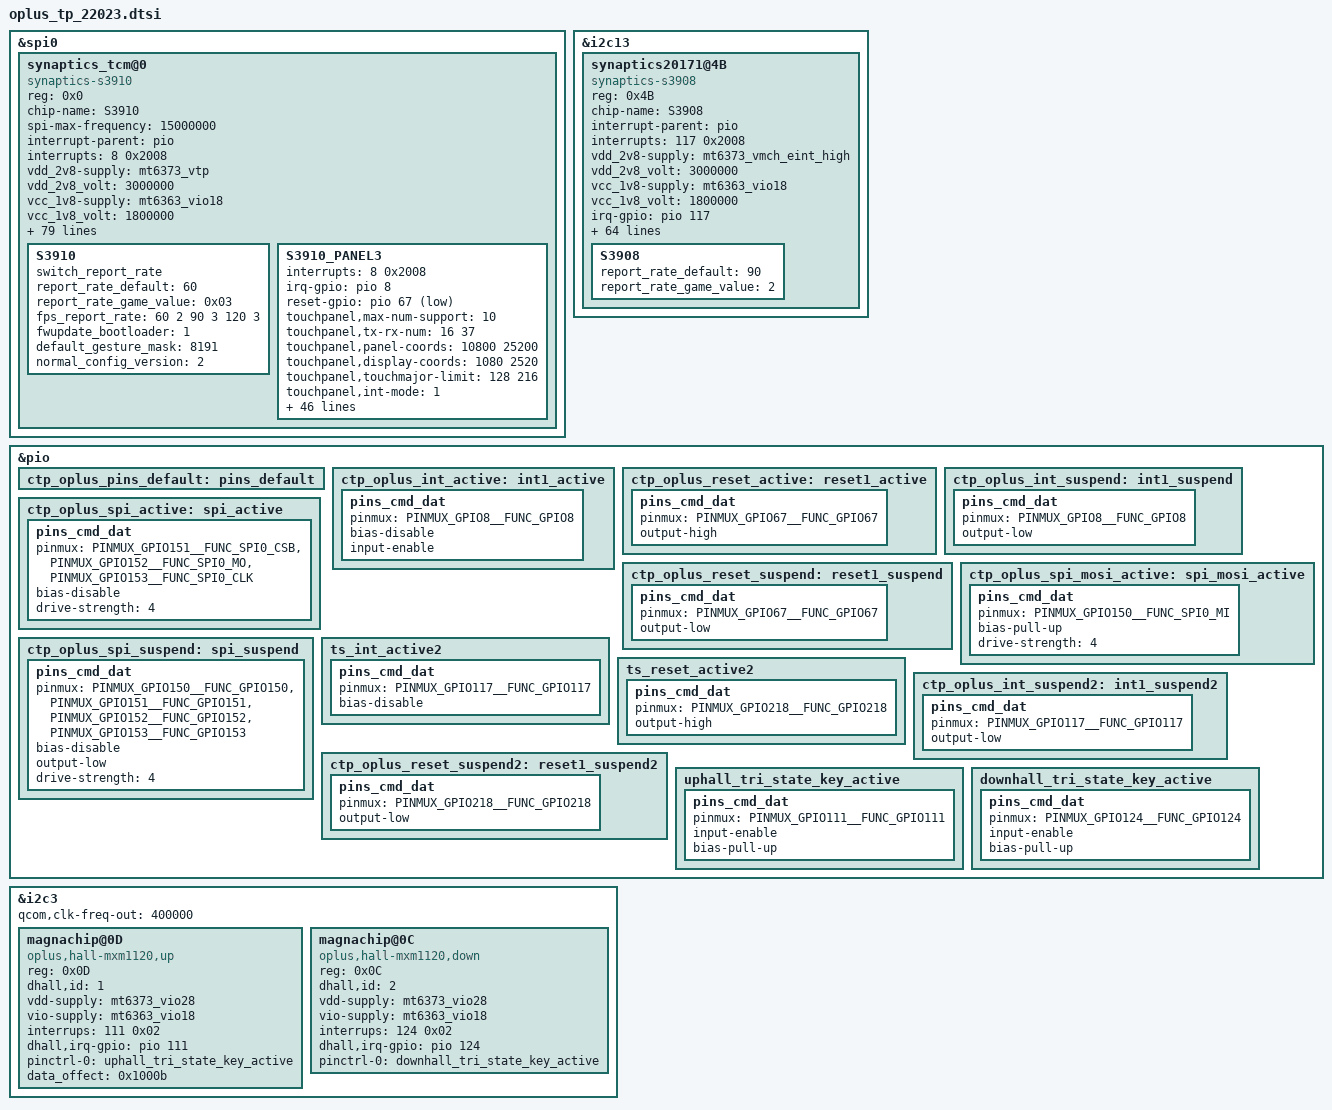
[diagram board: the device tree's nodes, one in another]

&spi0{
	status = "okay";
	#address-cells = <1>;
	#size-cells = <0>;

	synaptics_tcm@0{
		compatible = "synaptics-s3910";
		reg = <0x0>;
		chip-name = "S3910";
		status = "okay";
		spi-max-frequency = <15000000>;
		/* Interrupt && Irq-gpio */
		interrupt-parent = <&pio>;
		interrupts = <8 0x2008>;

		/* Power Config */
		//enable2v8_gpio  = <&pio 164 0x1>;
		vdd_2v8-supply  = <&mt6373_vtp>;
		vdd_2v8_volt = <3000000>;
		vcc_1v8-supply  = <&mt6363_vio18>;
		vcc_1v8_volt = <1800000>;

		/* Other HW Resource */
		irq-gpio = <&pio 8 0x2008>;
		reset-gpio = <&pio 67 0x1>;

		pinctrl-names = "default",  "oplus_int_active",
		"oplus_reset_active", "oplus_int_suspend",
		"oplus_reset_suspend", "oplus_spi_active",
		"oplus_spi_suspend";
		pinctrl-0 = <&ctp_oplus_pins_default>;
		pinctrl-1 = <&ctp_oplus_int_active>;
		pinctrl-2 = <&ctp_oplus_reset_active>;
		pinctrl-3 = <&ctp_oplus_int_suspend>;
		pinctrl-4 = <&ctp_oplus_reset_suspend>;
		pinctrl-5 = <&ctp_oplus_spi_active>, <&ctp_oplus_spi_mosi_active>;
		pinctrl-6 = <&ctp_oplus_spi_suspend>;

		touchpanel,max-num-support = <10>;
		touchpanel,tx-rx-num = <17 40>;
		earsense,tx-rx-num = <17 18>;
		touchpanel,panel-coords = <10800 25200>;
		touchpanel,display-coords = <1080 2520>;
		touchpanel,touchmajor-limit = <128 216>;
		touchpanel,elimination-range = <20 200 200>;
		touchpanel,int-mode = <1>; /*0: interrupt and disable, 1:interrupt and not disable*/
		touchpanel,smooth-level = <0 1 2 5 8 9>;
		touchpanel,smooth-level-charging = <0 2 4 8 9 10>;
		touchpanel,sensitive-level = <0 70 55 40 25 10>;
		touchpanel,single-optimized-time = <8>;
		touchpanel,high-frame-rate-time = <60>;

		touchpanel,tp-index = <0>;
		vid_len = <2>;
		panel_type = <3 8>; /*type:3 BOE  type:8 SAMSUNG*/
		platform_support_project = <22023 22223>;
		platform_support_project_dir = <22023 22023>;
		platform_support_project_commandline = "AC068_P_3_A0001_fhd_cmd","oplus22023_samsung_amf680cm01_fhd_dsi_cmd";

		prevention,curved_screen_V2;
		prevention,grip_disable_level = <6>;
		prevention,updelay_time_ms = <30>;
		prevention,makeup_cnt_weight = <5 1 2 2 2>;
		prevention,large_corner_range = <960 2400>;
		prevention,large_corner_judge_condition = <850 100 800 7 7>;
		prevention,trx_reject_condition = <8 7 7>;
		prevention,trx_strict_reject_condition = <8 6 6>;
		prevention,large_judge_time_ms = <500 50 30>;
		prevention,large_exit_condition = <8 8 2>;
		prevention,single_channel_width = <160 160>;
		prevention,normal_tap_condition = <5 350>;
		prevention,long_edge_condition = <310 220 200 60>;
		prevention,long_strict_edge_condition = <120 60>;
		prevention,long_fingerhold_condition = <70 6 4 4>;
		prevention,short_edge_condition = <280 180 180 80>;
		prevention,short_strict_edge_condition = <160 60>;
		prevention,large_strict_exit_condition = <6 6>;
		prevention,top_corner_config = <250 750 100>;
		prevention,edge_swipe_config = <150 700>;

		/* SW Support Feature Control */
		regulator_count_not_support;
		black_gesture_support;
		sportify_aod_gesture_support;
		pressure_report_support;
		charger_pump_support;
		game_switch_support;
		smart_gesture_support;
		spi_port_support;
		fw_update_app_support;
		fingerprint_underscreen_support;
		exception_upload_support;
		freq_hop_simulate_support;
		report_flow_unlock_support;
		screenoff_fingerprint_info_support;
		irq_need_dev_resume_ok;
		enable_point_auto_change;
		report_rate_white_list_support;
		kernel_grip_support;
		//grip_no_driver_support;
		health_monitor_support;
		black_gesture_indep_support;
		algorithm_support;
		snr_read_support;
		palm_to_sleep_support;
		tp_data_record_support;
		/*
		 *Virtual Key Config:
		 *1:touchpanel,button-type: <virtualkey_type  supportted_button-map>
		 *virtualkey_type:
		 *Type 1: using board_properties
		 *Type 2: using same IC (button zone&& touch zone are seprate)
		 *Type 3: using diffrent IC (button zone&& touch zone are seprate)
		 *Type 4: No need of virtual key process
		 *supportted_button-map:select|menu|home|back
		 *
		 *2:touchpanel,button-map
		 *type (X1,Y1)(X2,Y2)(X3,Y3)(Width_X,Hight_Y)--Only when button-type is 0
		 */
		touchpanel,button-type = <4>;
		touchpanel.button-TRx = <0 0>;

		S3910 {
			switch_report_rate;
			report_rate_default = <60>;
			report_rate_game_value = <0x03>;
			fps_report_rate = <60 2 90 3 120 3>;//1:360Hz 2:125Hz 3:240Hz
			fwupdate_bootloader = <1>;
			default_gesture_mask = <8191>;
			normal_config_version = <2>;
		};

		S3910_PANEL3 {
			interrupts = <8 0x2008>;
			irq-gpio = <&pio 8 0x2008>;
			reset-gpio = <&pio 67 0x1>;

			touchpanel,max-num-support = <10>;
			touchpanel,tx-rx-num = <16 37>;
			touchpanel,panel-coords = <10800 25200>;
			touchpanel,display-coords = <1080 2520>;
			touchpanel,touchmajor-limit = <128 216>;
			touchpanel,int-mode = <1>; /*0: interrupt and disable, 1:interrupt and not disable*/
			touchpanel,smooth-level = <0 1 2 5 8 9>;
			touchpanel,smooth-level-charging = <0 2 4 8 9 10>;
			touchpanel,sensitive-level = <0 140 110 80 50 20>;
			touchpanel,single-optimized-time = <8>;
			touchpanel,high-frame-rate-time = <60>;

			prevention,curved_screen_V2;
			prevention,grip_disable_level = <6>;
			prevention,updelay_time_ms = <30>;
			prevention,makeup_cnt_weight = <5 1 2 2 2>;
			prevention,large_corner_range = <960 2400>;
			prevention,large_corner_judge_condition = <850 100 800 7 7>;
			prevention,trx_reject_condition = <8 7 7>;
			prevention,trx_strict_reject_condition = <8 6 6>;
			prevention,large_judge_time_ms = <500 50 30>;
			prevention,large_exit_condition = <8 8 2>;
			prevention,single_channel_width = <160 160>;
			prevention,normal_tap_condition = <5 350>;
			prevention,long_edge_condition = <310 220 200 60>;
			prevention,long_strict_edge_condition = <120 60>;
			prevention,long_fingerhold_condition = <70 6 4 4>;
			prevention,short_edge_condition = <280 180 180 80>;
			prevention,short_strict_edge_condition = <160 60>;
			prevention,large_strict_exit_condition = <6 6>;
			prevention,top_corner_config = <250 750 100>;
			prevention,edge_swipe_config = <150 700>;

			prevention,curved_screen_V4;
			prevention,long_eliminate_point_type = <2 14400 10560 270 27720 300 1>;
			prevention,long_fingerhold_condition2 = <650 2000 0 0>;
			prevention,top_corner_config2 = <3 80 600 1500 0>;
			prevention,hor_long_top_corner_config = <350 2270 0 0>;
			prevention,top_middle_config = <14400 1000 1000 0>;
			prevention,corner_eliminate_point_type = <0 1380 2280 1>;
			prevention,finger_hold_max_rx_exit_distance = <5 350 2300>;
			prevention,max_rx_exit_distance = <1 5 150 350 2000>;
			prevention,dynamic_finger_hold_exit_distance = <1 350 2300 450>;
                        tp_data_record_support;
		};
	};

};

&i2c13 {
	status = "okay";
	synaptics20171@4B {
        status = "okay";
		compatible = "synaptics-s3908";
		reg = <0x4B>;
		chip-name = "S3908";

		/* Interrupt && Irq-gpio */
		interrupt-parent = <&pio>;
		interrupts = <117 0x2008>;

		/* Power Config */
		vdd_2v8-supply  = <&mt6373_vmch_eint_high>;
		vdd_2v8_volt = <3000000>;
		vcc_1v8-supply  = <&mt6363_vio18>;
		vcc_1v8_volt = <1800000>;
		/* Other HW Resource */

		irq-gpio = <&pio 117 0x2008>;
		reset-gpio = <&pio 218 0x1>;
		pinctrl-names = "default";
		pinctrl-0 = <&ts_int_active2 &ts_reset_active2>;

		touchpanel,max-num-support = <10>;
		touchpanel,tx-rx-num = <9 17>;
		touchpanel,panel-coords = <382 720>;
		touchpanel,display-coords = <382 720>;
		touchpanel,touchmajor-limit = <0 0>;
		touchpanel,elimination-range = <20 200 200>;
		touchpanel,int-mode = <1>; /*0: interrupt and disable, 1:interrupt and not disable*/
		touchpanel,smooth-level = <0 1 2 3 8 10>;
		touchpanel,sensitive-level = <0 88 70 64 45 10>;

		touchpanel,tp-index = <1>;
		vid_len = <2>;
		panel_type = <3>; /*type:3 BOE*/

		platform_support_project = <22023 22223>;
		platform_support_project_dir = <22023 22023>;
		platform_support_project_commandline = "default_commandline","default_commandline";

		prevention,curved_screen_V2;
		prevention,grip_disable_level = <6>;
		prevention,updelay_time_ms = <30>;
		prevention,makeup_cnt_weight = <4 1 2 2 2>;
		prevention,large_corner_range = <80 90>;
		prevention,large_corner_judge_condition = <500 100 100 6 6>;
		prevention,trx_reject_condition = <9 7 7>;
		prevention,trx_strict_reject_condition = <8 5 5>;
		prevention,large_judge_time_ms = <500 50 30>;
		prevention,large_exit_condition = <8 8 2>;
		prevention,single_channel_width = <32 32>;
		prevention,normal_tap_condition = <10 300>;
		prevention,long_edge_condition = <350 130 180 100>;
		prevention,long_strict_edge_condition = <160 60>;
		prevention,long_fingerhold_condition = <100 6 4 4>;
		prevention,short_edge_condition = <180 130 180 220>;
		prevention,short_strict_edge_condition = <160 60>;
		prevention,large_strict_exit_condition = <4 4>;
		prevention,top_corner_config = <0 0 0>;
		prevention,edge_swipe_config = <30 100>;

		/* SW Support Feature Control */
		health_monitor_support;
		black_gesture_support;
		black_gesture_indep_support;
		sportify_aod_gesture_support;
		charger_pump_support;
		lcd_tp_refresh_support;
		enable_point_auto_change;
		fw_update_app_support;
		smart_gesture_support;
		game_switch_support;
		report_flow_unlock_support;
		kernel_grip_support;
		freq_hop_simulate_support;
 		pressure_report_support;
		exception_upload_support;
		touchpanel,single-optimized-time = <8>;
 		touchpanel,high-frame-rate-time = <60>;
		regulator_count_not_support;
		palm_to_sleep_support;
		suspend_work_support;
		/*
		 *Virtual Key Config:
		 *1:touchpanel,button-type: <virtualkey_type  supportted_button-map>
		 *virtualkey_type:
		 *Type 1: using board_properties
		 *Type 2: using same IC (button zone&& touch zone are seprate)
		 *Type 3: using diffrent IC (button zone&& touch zone are seprate)
		 *Type 4: No need of virtual key process
		 *supportted_button-map:select|menu|home|back
		 *
		 *2:touchpanel,button-map
		 *type (X1,Y1)(X2,Y2)(X3,Y3)(Width_X,Hight_Y)--Only when button-type is 0
		 */
		touchpanel,button-type = <4>;
		touchpanel.button-TRx = <0 0>;

		S3908 {
			report_rate_default = <90>;
			report_rate_game_value = <2>;
		};
	};
};

&pio {
	ctp_oplus_pins_default: pins_default {
	};
	ctp_oplus_int_active: int1_active {
		pins_cmd_dat {
			pinmux = <PINMUX_GPIO8__FUNC_GPIO8>;
			bias-disable;
			input-enable;
		};
	};
	ctp_oplus_reset_active: reset1_active {
		pins_cmd_dat {
			pinmux = <PINMUX_GPIO67__FUNC_GPIO67>;
			output-high;
		};
	};
	ctp_oplus_int_suspend: int1_suspend {
		pins_cmd_dat {
			pinmux = <PINMUX_GPIO8__FUNC_GPIO8>;
			output-low;
		};
	};
	ctp_oplus_reset_suspend: reset1_suspend {
		pins_cmd_dat {
			pinmux = <PINMUX_GPIO67__FUNC_GPIO67>;
			output-low;
		};
	};
	ctp_oplus_spi_active: spi_active {
		pins_cmd_dat {
			pinmux = <PINMUX_GPIO151__FUNC_SPI0_CSB>,
				<PINMUX_GPIO152__FUNC_SPI0_MO>,
				<PINMUX_GPIO153__FUNC_SPI0_CLK>;
			bias-disable;
			drive-strength = <4>;
		};
	};
	ctp_oplus_spi_mosi_active: spi_mosi_active {
		pins_cmd_dat {
			pinmux = <PINMUX_GPIO150__FUNC_SPI0_MI>;
			bias-pull-up;
			drive-strength = <4>;
		};
	};
	ctp_oplus_spi_suspend: spi_suspend {
		pins_cmd_dat {
			pinmux = < PINMUX_GPIO150__FUNC_GPIO150>,
				< PINMUX_GPIO151__FUNC_GPIO151>,
				<PINMUX_GPIO152__FUNC_GPIO152>,
				< PINMUX_GPIO153__FUNC_GPIO153>;
			bias-disable;
			output-low;
			drive-strength = <4>;
		};
	};

	ts_int_active2: ts_int_active2 {
		pins_cmd_dat {
			pinmux = <PINMUX_GPIO117__FUNC_GPIO117>;
			bias-disable;
		};
	};
	ts_reset_active2: ts_reset_active2 {
		pins_cmd_dat {
			pinmux = <PINMUX_GPIO218__FUNC_GPIO218>;
			output-high;
		};
	};
	ctp_oplus_int_suspend2: int1_suspend2 {
		pins_cmd_dat {
			pinmux = <PINMUX_GPIO117__FUNC_GPIO117>;
			output-low;
		};
	};
	ctp_oplus_reset_suspend2: reset1_suspend2 {
		pins_cmd_dat {
			pinmux = <PINMUX_GPIO218__FUNC_GPIO218>;
			output-low;
		};
	};
};

&i2c3 {
        status = "ok";
        qcom,clk-freq-out = <400000>;
        magnachip@0D {
                compatible = "oplus,hall-mxm1120,up";
                reg = <0x0D>;
                dhall,id = <1>;
                vdd-supply = <&mt6373_vio28>;
                vio-supply = <&mt6363_vio18>;
                //interrupt-parent = <&tlmm>;
                interrups = <111 0x02>;
                dhall,irq-gpio = <&pio 111 0x2008>;
                pinctrl-names = "uphall_tri_state_key_active";
                pinctrl-0 = <&uphall_tri_state_key_active>;
                data_offect = <0x1000b>;
        };
        magnachip@0C {
                compatible = "oplus,hall-mxm1120,down";
                reg = <0x0C>;
                dhall,id = <2>;
                vdd-supply = <&mt6373_vio28>;
                vio-supply = <&mt6363_vio18>;
                //interrupt-parent = <&tlmm>;
                interrups = <124 0x02>;
                dhall,irq-gpio = <&pio 124 0x2008>;
                pinctrl-names = "downhall_tri_state_key_active";
                pinctrl-0 = <&downhall_tri_state_key_active>;
        };
};

&pio {
    uphall_tri_state_key_active: uphall_tri_state_key_active {
                pins_cmd_dat {
                        pinmux = <PINMUX_GPIO111__FUNC_GPIO111>;
                        input-enable;
                        bias-pull-up;
                };
        };
    downhall_tri_state_key_active: downhall_tri_state_key_active {
                pins_cmd_dat {
                        pinmux = <PINMUX_GPIO124__FUNC_GPIO124>;
                        input-enable;
                        bias-pull-up;
                };
        };
};
